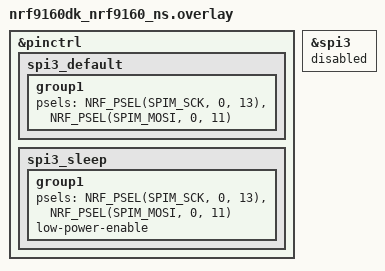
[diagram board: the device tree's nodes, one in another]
/* Copyright (c) 2022 Nordic Semiconductor ASA
 *
 * SPDX-License-Identifier: LicenseRef-Nordic-5-Clause
 */

&pinctrl {
	spi3_default: spi3_default {
		group1 {
			psels = <NRF_PSEL(SPIM_SCK, 0, 13)>,
				<NRF_PSEL(SPIM_MOSI, 0, 11)>;
		};
	};

	spi3_sleep: spi3_sleep {
		group1 {
			psels = <NRF_PSEL(SPIM_SCK, 0, 13)>,
				<NRF_PSEL(SPIM_MOSI, 0, 11)>;
			low-power-enable;
		};
	};
};

&spi3 {
	/* Disabled in non-secure image. */
	status = "disabled";
};
